# XHSC_HC32L021 register map
Vendor: XHSC Co.Ltd; Series: ARMCM4; File version: 1.2
CPU: CM4 r0p0, little endian, no MPU, no FPU, 3 interrupt priority bits
Registers are 32-bit, read-write, reset 0x0 unless marked. A register's access mark holds for its fields unless they carry their own. Offsets are from the block's base; lines under a group give offsets from that group; [hi:lo] are bit positions; {n}, {i} and the like mark numbered series; 'fields as' and 'values as' point back to an identical list; <NAME> marks a mode.

## Memory map
0x40000000 LPUART0 size 0x24 — desc LPUART
0x40000800 SPI0 size 0x1C — desc SPI
0x40001000 IWDT size 0x94
0x40001400 RTC size 0x64
0x40001800 BTIM0 size 0x50 — desc BTIM
0x40001800 GTIM0 size 0x330 — desc GTIM
0x40001900 BTIM1 size 0x50 — desc BTIM
0x40001A00 BTIM2 size 0x50 — desc BTIM
0x40001C00 BTIM3 size 0x50 — desc BTIM
0x40001C00 GTIM1 size 0x330 — desc GTIM
0x40001D00 BTIM4 size 0x50 — desc BTIM
0x40001E00 BTIM5 size 0x50 — desc BTIM
0x40002400 ADC size 0xD0
0x40002800 VC size 0x20
0x40002C00 LVD size 0x8
0x40008000 LPUART1 size 0x24 — desc LPUART
0x40008C00 TRNG size 0x14
0x40009000 CTRIM size 0x2C
0x40009800 ATIM3_MODE0 size 0x34
0x40009800 ATIM3_MODE1 size 0x40
0x40009800 ATIM3_MODE23 size 0x64
0x4000BC00 HSI2C0 size 0x154 — desc HSI2C
0x40020000 FLASH size 0x70
0x40020C00 GPIOA size 0x114 — desc GPIO
0x40020C00 GPIOAUX size 0x334
0x40020C40 GPIOB size 0x214 — desc GPIO
0x40021800 SYSCTRL size 0x3C

## ADC
Base 0x40002400
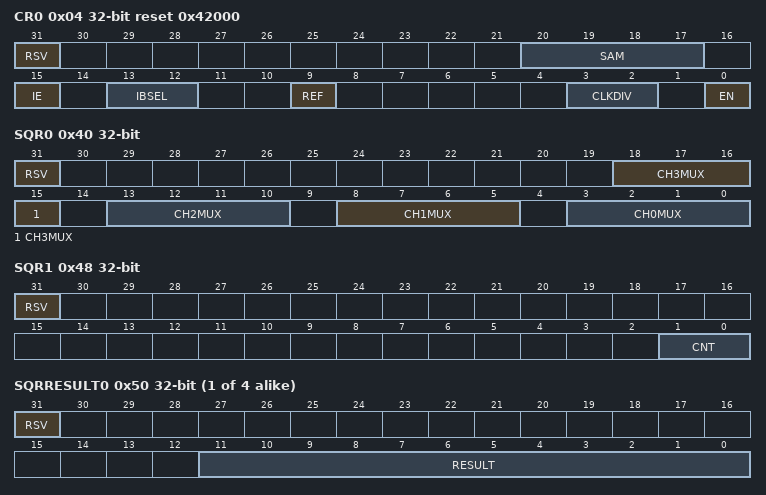
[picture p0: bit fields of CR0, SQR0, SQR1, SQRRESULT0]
0x04 CR0 reset 0x42000 (reset mask 0xFFFF)
  [31] RSV, [20:17] SAM, [15] IE, [13:12] IBSEL, [9] REF, [3:2] CLKDIV, [0] EN
0x40 SQR0 (reset mask 0xF)
  [31] RSV, [5n+3:5n] CH{n}MUX (n=0..3)
0x48 SQR1 (reset mask 0x1)
  [31] RSV, [1:0] CNT
{0x50+4i} SQRRESULT{i} ro (reset mask 0xFFF) (i=0..3)
  [31] RSV rw, [11:0] RESULT
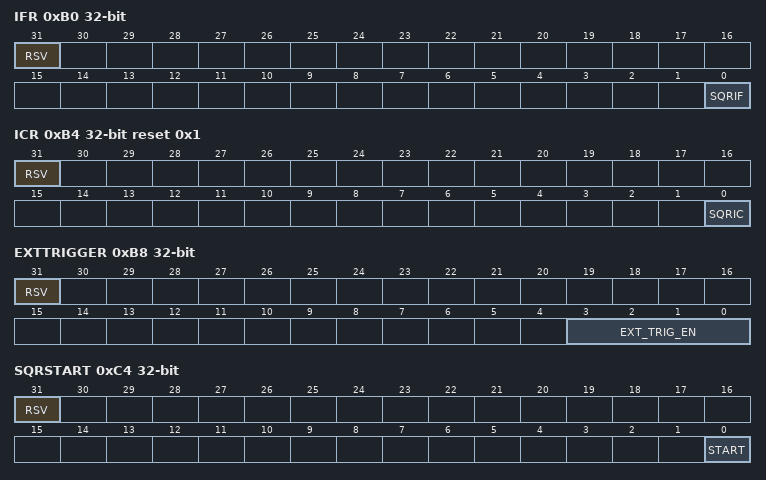
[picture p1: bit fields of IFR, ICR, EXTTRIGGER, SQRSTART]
0xB0 IFR ro (reset mask 0x1)
  [31] RSV rw, [0] SQRIF
0xB4 ICR wo reset 0x1 (reset mask 0x1)
  [31] RSV rw, [0] SQRIC
0xB8 EXTTRIGGER (reset mask 0x7)
  [31] RSV, [3:0] EXT_TRIG_EN
0xC4 SQRSTART (reset mask 0x1)
  [31] RSV, [0] START wo

## ATIM3_MODE0
Base 0x40009800
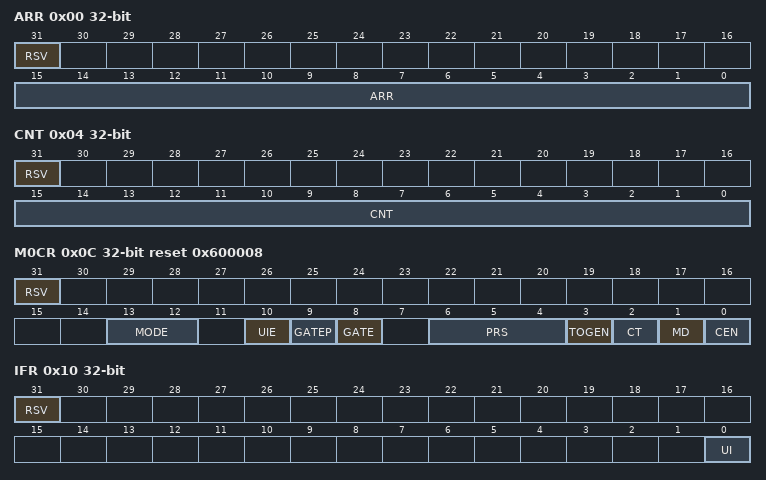
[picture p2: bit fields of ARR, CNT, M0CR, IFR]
0x00 ARR (reset mask 0xFFFF)
  [31] RSV, [15:0] ARR
0x04 CNT (reset mask 0xFFFF)
  [31] RSV, [15:0] CNT
0x08 CNT32
0x0C M0CR reset 0x600008 (reset mask 0x377C)
  [31] RSV, [13:12] MODE, [10] UIE, [9] GATEP, [8] GATE, [6:4] PRS, [3] TOGEN, [2] CT, [1] MD, [0] CEN
0x10 IFR ro (reset mask 0x1)
  [31] RSV rw, [0] UI
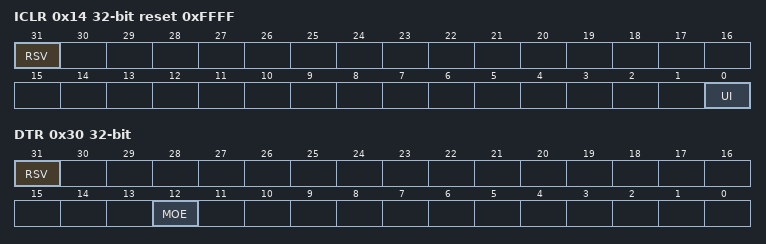
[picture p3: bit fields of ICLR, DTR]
0x14 ICLR wo reset 0xFFFF (reset mask 0x1)
  [31] RSV rw, [0] UI
0x30 DTR (reset mask 0x1000)
  [31] RSV, [12] MOE

## ATIM3_MODE1
Base 0x40009800; alternate view of ATIM3_MODE0
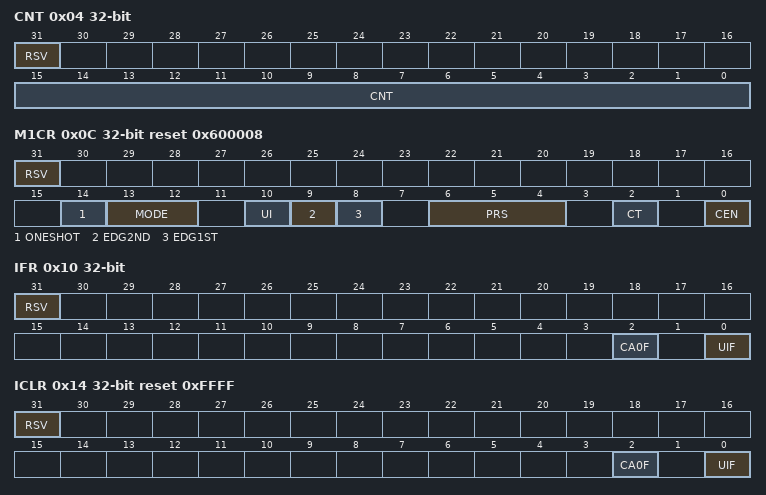
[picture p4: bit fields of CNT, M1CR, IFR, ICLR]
0x04 CNT (reset mask 0xFFFF)
  [31] RSV, [15:0] CNT
0x0C M1CR reset 0x600008 (reset mask 0x7775)
  [31] RSV, [14] ONESHOT, [13:12] MODE, [10] UI, [9] EDG2ND, [8] EDG1ST, [6:4] PRS, [2] CT, [0] CEN
0x10 IFR ro (reset mask 0x5)
  [31] RSV rw, [2] CA0F, [0] UIF
0x14 ICLR wo reset 0xFFFF (reset mask 0x5)
  [31] RSV rw, [2] CA0F, [0] UIF
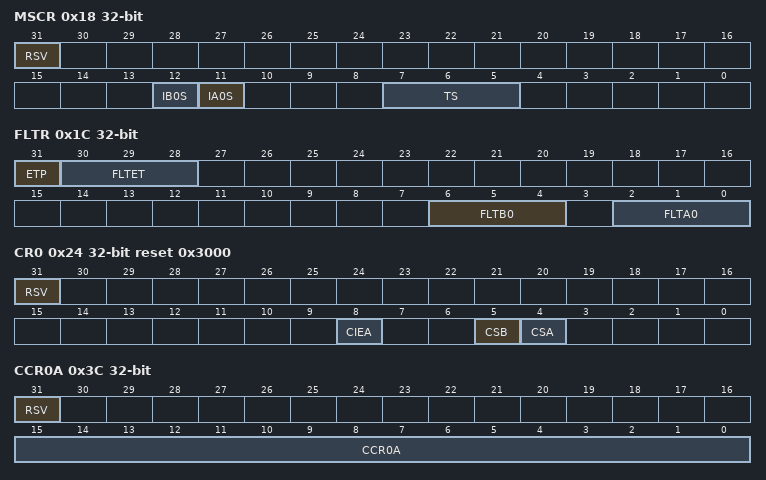
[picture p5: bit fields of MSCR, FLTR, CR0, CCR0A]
0x18 MSCR (reset mask 0x18E0)
  [31] RSV, [12] IB0S, [11] IA0S, [7:5] TS
0x1C FLTR
  [31] ETP, [30:28] FLTET, [6:4] FLTB0, [2:0] FLTA0
0x24 CR0 reset 0x3000 (reset mask 0x130)
  [31] RSV, [8] CIEA, [5] CSB, [4] CSA
0x3C CCR0A (reset mask 0xFFFF)
  [31] RSV, [15:0] CCR0A

## ATIM3_MODE23
Base 0x40009800; alternate view of ATIM3_MODE0
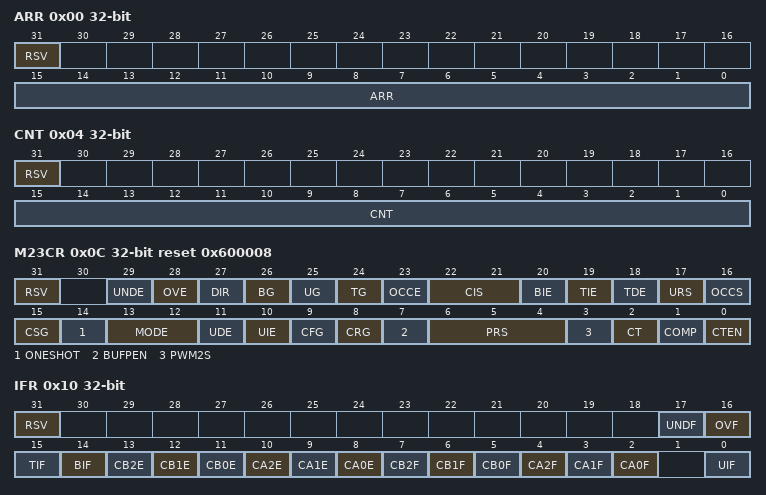
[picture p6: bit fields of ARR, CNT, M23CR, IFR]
0x00 ARR (reset mask 0xFFFF)
  [31] RSV, [15:0] ARR
0x04 CNT (reset mask 0xFFFF)
  [31] RSV, [15:0] CNT
0x0C M23CR reset 0x600008 (reset mask 0x3FFFFFFF)
  [31] RSV, [29] UNDE, [28] OVE, [27] DIR, [26] BG wo, [25] UG wo, [24] TG wo, [23] OCCE, [22:21] CIS, [20] BIE, [19] TIE, [18] TDE, [17] URS, [16] OCCS, [15] CSG, [14] ONESHOT, [13:12] MODE, [11] UDE, [10] UIE, [9] CFG, [8] CRG, [7] BUFPEN, [6:4] PRS, [3] PWM2S, [2] CT, [1] COMP, [0] CTEN
0x10 IFR ro (reset mask 0xFFFFD)
  [31] RSV, [17] UNDF, [16] OVF, [15] TIF, [14] BIF, [13] CB2E, [12] CB1E, [11] CB0E, [10] CA2E, [9] CA1E, [8] CA0E, [7] CB2F, [6] CB1F, [5] CB0F, [4] CA2F, [3] CA1F, [2] CA0F, [0] UIF
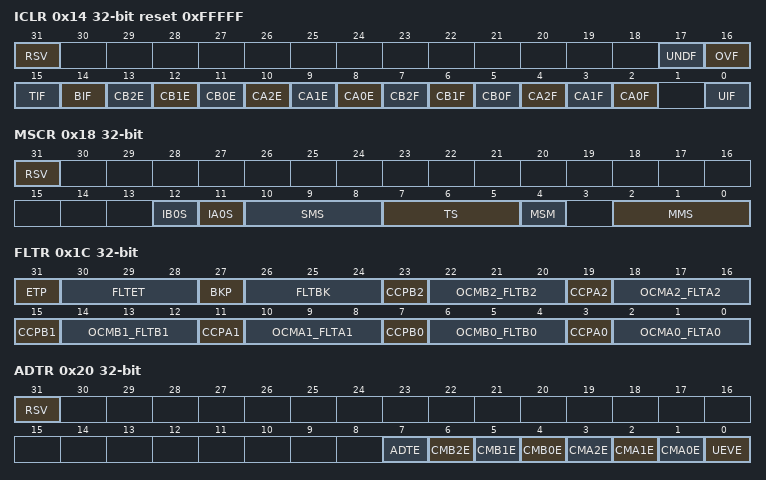
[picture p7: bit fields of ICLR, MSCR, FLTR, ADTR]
0x14 ICLR wo reset 0xFFFFF (reset mask 0xFFFFD)
  [31] RSV rw, [17] UNDF rw, [16] OVF rw, [15] TIF, [14] BIF, [13] CB2E, [12] CB1E, [11] CB0E, [10] CA2E, [9] CA1E, [8] CA0E, [7] CB2F, [6] CB1F, [5] CB0F, [4] CA2F, [3] CA1F, [2] CA0F, [0] UIF
0x18 MSCR (reset mask 0x1FFF)
  [31] RSV, [12] IB0S, [11] IA0S, [10:8] SMS, [7:5] TS, [4] MSM, [2:0] MMS
0x1C FLTR
  [31] ETP, [30:28] FLTET, [27] BKP, [26:24] FLTBK, [23] CCPB2, [22:20] OCMB2_FLTB2, [19] CCPA2, [18:16] OCMA2_FLTA2, [15] CCPB1, [14:12] OCMB1_FLTB1, [11] CCPA1, [10:8] OCMA1_FLTA1, [7] CCPB0, [6:4] OCMB0_FLTB0, [3] CCPA0, [2:0] OCMA0_FLTA0
0x20 ADTR (reset mask 0xFF)
  [31] RSV, [7] ADTE, [6] CMB2E, [5] CMB1E, [4] CMB0E, [3] CMA2E, [2] CMA1E, [1] CMA0E, [0] UEVE
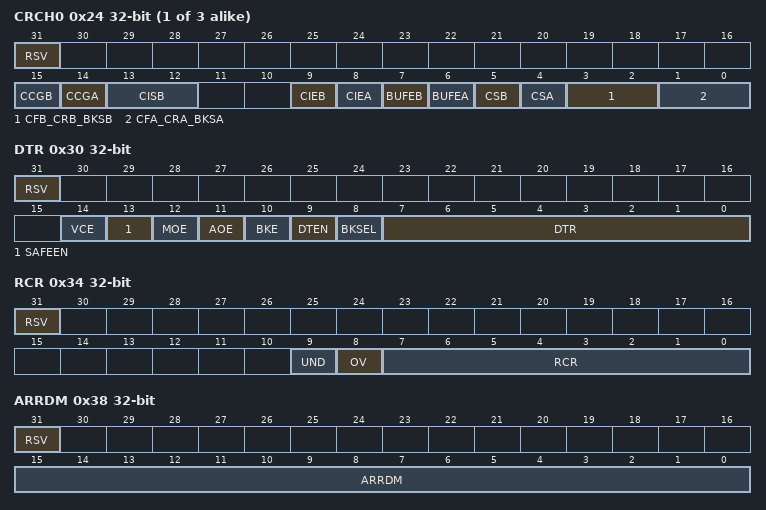
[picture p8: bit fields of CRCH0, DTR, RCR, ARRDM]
{0x24+4i} CRCH{i} (reset mask 0xFFFF) (i=0..2)
  [31] RSV, [15] CCGB, [14] CCGA, [13:12] CISB, [9] CIEB, [8] CIEA, [7] BUFEB, [6] BUFEA, [5] CSB, [4] CSA, [3:2] CFB_CRB_BKSB, [1:0] CFA_CRA_BKSA
0x30 DTR (reset mask 0x7FFF)
  [31] RSV, [14] VCE, [13] SAFEEN, [12] MOE, [11] AOE, [10] BKE, [9] DTEN, [8] BKSEL, [7:0] DTR
0x34 RCR (reset mask 0x3FF)
  [31] RSV, [9] UND, [8] OV, [7:0] RCR
0x38 ARRDM (reset mask 0xFFFF)
  [31] RSV, [15:0] ARRDM
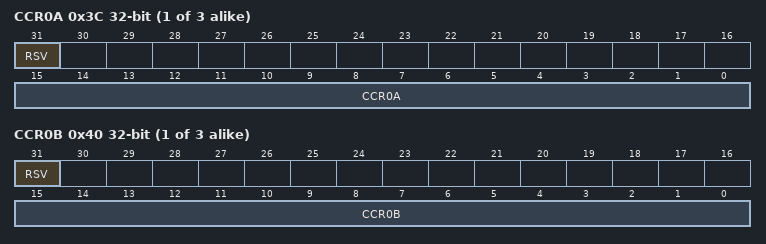
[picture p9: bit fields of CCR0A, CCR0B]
{0x3C+8i} CCR{i}A (reset mask 0xFFFF) (i=0..2)
  [31] RSV, [15:0] CCR{i}A
{0x40+8i} CCR{i}B (reset mask 0xFFFF) (i=0..2)
  [31] RSV, [15:0] CCR{i}B
